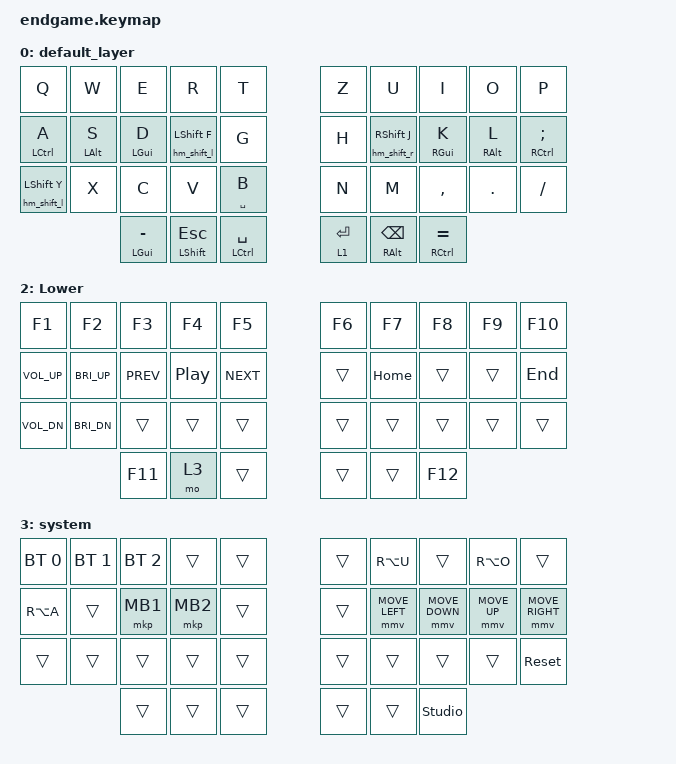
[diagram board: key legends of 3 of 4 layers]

/*
 * Copyright (c) 2021 The ZMK Contributors
 *
 * SPDX-License-Identifier: MIT
 */

#include <behaviors.dtsi>
#include <dt-bindings/zmk/keys.h>
#include <dt-bindings/zmk/bt.h>

#include "../boards/shields/endgame/includes/settings.dtsi"
#include "../boards/shields/endgame/includes/combos.dtsi"
#include "../boards/shields/endgame/includes/homerow_mods.dtsi"

/ {
    keymap {
        compatible = "zmk,keymap";

        default_layer {
            bindings = <
    &kp Q        &kp W       &kp E               &kp R          &kp T            &kp Z        &kp U            &kp I            &kp O            &kp P
    &hm_l LCTRL A  &hm_l LALT S  &hm_l LEFT_GUI D &hm_shift_l LSHFT F  &kp G  &kp H  &hm_shift_r RSHFT J  &hm_r RIGHT_GUI K  &hm_r RIGHT_ALT L  &hm_r RCTRL SEMICOLON
    &hm_shift_l LSHFT Y        &kp X       &kp C               &kp V          &mt SPACE B      &kp N        &kp M            &kp COMMA        &kp PERIOD       &kp SLASH
    &hm LEFT_GUI MINUS                           &hm LSHFT ESC  &hm LCTRL SPACE  &lt 1 ENTER  &hm RALT BSPC                                      &hm RCTRL EQUAL
            >;
        };

        num_arrow {
            bindings = <
    &kp N1  &kp N2  &kp N3  &kp N4  &kp N5  &kp N6  &kp N7  &kp N8  &kp N9  &kp N0
     &trans &trans &trans &trans &trans  &trans &kp LEFT  &kp DOWN  &kp UP  &kp RIGHT
    &trans  &trans  &trans  &trans  &trans  &trans  &trans  &trans  &trans  &trans  &trans  &trans
    &trans        &trans  &mo 2  &trans  &kp DEL        &trans
            >;
        };

        lower {
            bindings = <
  &kp F1           &kp F2        &kp F3      &kp F4    &kp F5      &kp F6  &kp F7    &kp F8   &kp F9  &kp F10
  &kp C_VOLUME_UP  &kp C_BRI_UP  &kp C_PREV  &kp C_PP  &kp C_NEXT  &trans  &kp HOME  &trans   &trans  &kp END
  &kp C_VOL_DN     &kp C_BRI_DN  &trans      &trans    &trans      &trans  &trans    &trans   &trans  &trans
                                       &kp F11     &mo 3     &trans      &trans  &trans    &kp F12
            >;

            label = "Lower";
        };
        system {
            bindings = <
    &bt BT_SEL 0  &bt BT_SEL 1  &bt BT_SEL 2  &trans    &trans  &trans  &kp RA(U)       &trans          &kp RA(O)     &trans
    &kp RA(A)     &trans        &mkp MB1      &mkp MB2  &trans  &trans  &mmv MOVE_LEFT  &mmv MOVE_DOWN  &mmv MOVE_UP  &mmv MOVE_RIGHT
    &trans        &trans        &trans        &trans    &trans  &trans  &trans          &trans          &trans        &sys_reset
            &trans        &trans    &trans  &trans  &trans          &studio_unlock
            >;
        };
    };
};
;
